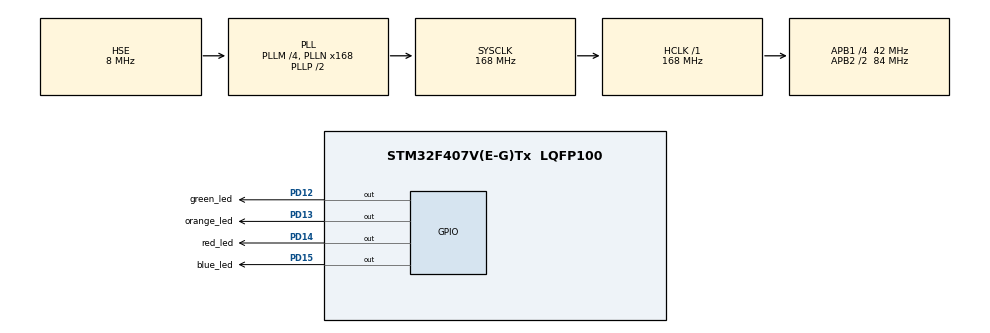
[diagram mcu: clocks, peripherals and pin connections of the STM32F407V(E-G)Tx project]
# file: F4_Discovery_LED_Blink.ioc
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Mcu.Family=STM32F4
Mcu.Name=STM32F407V(E-G)Tx
Mcu.Package=LQFP100
NVIC.PriorityGroup=NVIC_PRIORITYGROUP_0
PA13.Mode=Serial_Wire
PA13.Signal=SYS_JTMS-SWDIO
PA14.Mode=Serial_Wire
PA14.Signal=SYS_JTCK-SWCLK
PD12.GPIO_Label=green_led
PD12.Signal=GPIO_Output
PD13.GPIO_Label=orange_led
PD13.Signal=GPIO_Output
PD14.GPIO_Label=red_led
PD14.Signal=GPIO_Output
PD15.GPIO_Label=blue_led
PD15.Signal=GPIO_Output
PH0-OSC_IN.Mode=HSE-External-Oscillator
PH0-OSC_IN.Signal=RCC_OSC_IN
PH1-OSC_OUT.Mode=HSE-External-Oscillator
PH1-OSC_OUT.Signal=RCC_OSC_OUT
ProjectManager.HeapSize=0x200
ProjectManager.StackSize=0x400
ProjectManager.TargetToolchain=Makefile
RCC.48MHZClocksFreq_Value=48000000
RCC.AHBFreq_Value=168000000
RCC.APB1CLKDivider=RCC_HCLK_DIV4
RCC.APB1Freq_Value=42000000
RCC.APB1TimFreq_Value=84000000
RCC.APB2CLKDivider=RCC_HCLK_DIV2
RCC.APB2Freq_Value=84000000
RCC.APB2TimFreq_Value=168000000
RCC.CortexFreq_Value=168000000
RCC.HCLKFreq_Value=168000000
RCC.HSE_VALUE=8000000
RCC.HSI_VALUE=16000000
RCC.LSE_VALUE=32768
RCC.PLLM=4
RCC.PLLN=168
RCC.PLLQ=7
RCC.PLLSourceVirtual=RCC_PLLSOURCE_HSE
RCC.SYSCLKFreq_VALUE=168000000
RCC.SYSCLKSource=RCC_SYSCLKSOURCE_PLLCLK
RCC.VCOOutputFreq_Value=336000000
board=STM32F4DISCOVERY

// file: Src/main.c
/* USER CODE BEGIN Header */
/**
  ******************************************************************************
  * @file           : main.c
  * @brief          : Main program body
  ******************************************************************************
  ** This notice applies to any and all portions of this file
  * that are not between comment pairs USER CODE BEGIN and
  * USER CODE END. Other portions of this file, whether
  * inserted by the user or by software development tools
  * are owned by their respective copyright owners.
  *
  * COPYRIGHT(c) 2019 STMicroelectronics
  *
  * Redistribution and use in source and binary forms, with or without modification,
  * are permitted provided that the following conditions are met:
  *   1. Redistributions of source code must retain the above copyright notice,
  *      this list of conditions and the following disclaimer.
  *   2. Redistributions in binary form must reproduce the above copyright notice,
  *      this list of conditions and the following disclaimer in the documentation
  *      and/or other materials provided with the distribution.
  *   3. Neither the name of STMicroelectronics nor the names of its contributors
  *      may be used to endorse or promote products derived from this software
  *      without specific prior written permission.
  *
  * THIS SOFTWARE IS PROVIDED BY THE COPYRIGHT HOLDERS AND CONTRIBUTORS "AS IS"
  * AND ANY EXPRESS OR IMPLIED WARRANTIES, INCLUDING, BUT NOT LIMITED TO, THE
  * IMPLIED WARRANTIES OF MERCHANTABILITY AND FITNESS FOR A PARTICULAR PURPOSE ARE
  * DISCLAIMED. IN NO EVENT SHALL THE COPYRIGHT HOLDER OR CONTRIBUTORS BE LIABLE
  * FOR ANY DIRECT, INDIRECT, INCIDENTAL, SPECIAL, EXEMPLARY, OR CONSEQUENTIAL
  * DAMAGES (INCLUDING, BUT NOT LIMITED TO, PROCUREMENT OF SUBSTITUTE GOODS OR
  * SERVICES; LOSS OF USE, DATA, OR PROFITS; OR BUSINESS INTERRUPTION) HOWEVER
  * CAUSED AND ON ANY THEORY OF LIABILITY, WHETHER IN CONTRACT, STRICT LIABILITY,
  * OR TORT (INCLUDING NEGLIGENCE OR OTHERWISE) ARISING IN ANY WAY OUT OF THE USE
  * OF THIS SOFTWARE, EVEN IF ADVISED OF THE POSSIBILITY OF SUCH DAMAGE.
  *
  ******************************************************************************
  */
/* USER CODE END Header */

#include "main.h"

/* USER CODE BEGIN PV */

int x=100;

/* USER CODE END PV */

void SystemClock_Config(void);
static void MX_GPIO_Init(void);

int main(void)
{

  /* MCU Configuration--------------------------------------------------------*/

  /* Reset of all peripherals, Initializes the Flash interface and the Systick. */
  HAL_Init();

  /* Configure the system clock */
  SystemClock_Config();

  /* Initialize all configured peripherals */
  MX_GPIO_Init();

  /* Infinite loop */
  /* USER CODE BEGIN WHILE */
  while (1)
  {
HAL_GPIO_WritePin(GPIOD, green_led_Pin|orange_led_Pin|red_led_Pin|blue_led_Pin, GPIO_PIN_SET);
HAL_Delay(1000);
HAL_GPIO_WritePin(GPIOD, green_led_Pin|orange_led_Pin|red_led_Pin|blue_led_Pin, GPIO_PIN_RESET);
HAL_Delay(1000);
x++;

    /* USER CODE END WHILE */

  }
}

void SystemClock_Config(void)
{
  RCC_OscInitTypeDef RCC_OscInitStruct = {0};
  RCC_ClkInitTypeDef RCC_ClkInitStruct = {0};

  /**Configure the main internal regulator output voltage
  */
  __HAL_RCC_PWR_CLK_ENABLE();
  __HAL_PWR_VOLTAGESCALING_CONFIG(PWR_REGULATOR_VOLTAGE_SCALE1);
  /**Initializes the CPU, AHB and APB busses clocks
  */
  RCC_OscInitStruct.OscillatorType = RCC_OSCILLATORTYPE_HSE;
  RCC_OscInitStruct.HSEState = RCC_HSE_ON;
  RCC_OscInitStruct.PLL.PLLState = RCC_PLL_ON;
  RCC_OscInitStruct.PLL.PLLSource = RCC_PLLSOURCE_HSE;
  RCC_OscInitStruct.PLL.PLLM = 4;
  RCC_OscInitStruct.PLL.PLLN = 168;
  RCC_OscInitStruct.PLL.PLLP = RCC_PLLP_DIV2;
  RCC_OscInitStruct.PLL.PLLQ = 7;
  if (HAL_RCC_OscConfig(&RCC_OscInitStruct) != HAL_OK)
  {
    Error_Handler();
  }
  /**Initializes the CPU, AHB and APB busses clocks
  */
  RCC_ClkInitStruct.ClockType = RCC_CLOCKTYPE_HCLK|RCC_CLOCKTYPE_SYSCLK
                              |RCC_CLOCKTYPE_PCLK1|RCC_CLOCKTYPE_PCLK2;
  RCC_ClkInitStruct.SYSCLKSource = RCC_SYSCLKSOURCE_PLLCLK;
  RCC_ClkInitStruct.AHBCLKDivider = RCC_SYSCLK_DIV1;
  RCC_ClkInitStruct.APB1CLKDivider = RCC_HCLK_DIV4;
  RCC_ClkInitStruct.APB2CLKDivider = RCC_HCLK_DIV2;

  if (HAL_RCC_ClockConfig(&RCC_ClkInitStruct, FLASH_LATENCY_5) != HAL_OK)
  {
    Error_Handler();
  }
}

static void MX_GPIO_Init(void)
{
  GPIO_InitTypeDef GPIO_InitStruct = {0};

  /* GPIO Ports Clock Enable */
  __HAL_RCC_GPIOH_CLK_ENABLE();
  __HAL_RCC_GPIOD_CLK_ENABLE();
  __HAL_RCC_GPIOA_CLK_ENABLE();

  /*Configure GPIO pin Output Level */
  HAL_GPIO_WritePin(GPIOD, green_led_Pin|orange_led_Pin|red_led_Pin|blue_led_Pin, GPIO_PIN_RESET);

  /*Configure GPIO pins : green_led_Pin orange_led_Pin red_led_Pin blue_led_Pin */
  GPIO_InitStruct.Pin = green_led_Pin|orange_led_Pin|red_led_Pin|blue_led_Pin;
  GPIO_InitStruct.Mode = GPIO_MODE_OUTPUT_PP;
  GPIO_InitStruct.Pull = GPIO_NOPULL;
  GPIO_InitStruct.Speed = GPIO_SPEED_FREQ_LOW;
  HAL_GPIO_Init(GPIOD, &GPIO_InitStruct);

}

void Error_Handler(void)
{
}

/************************ (C) COPYRIGHT STMicroelectronics *****END OF FILE****/
